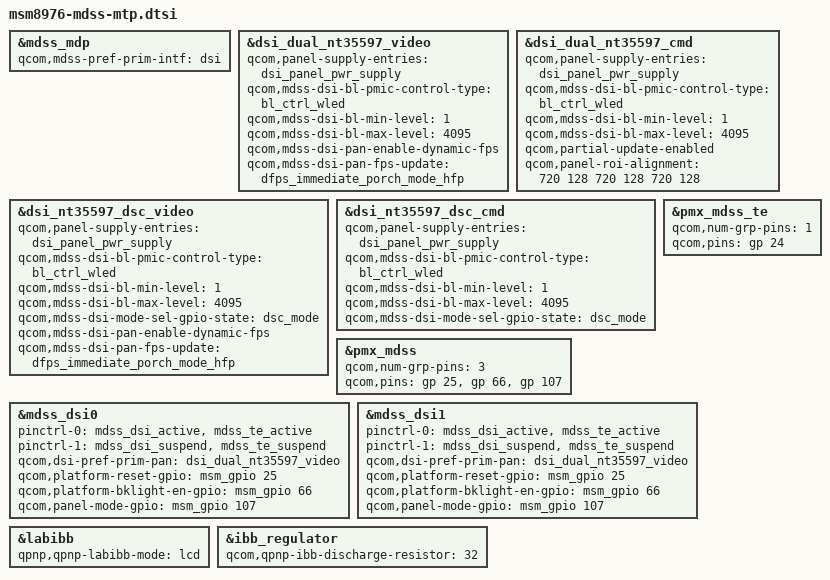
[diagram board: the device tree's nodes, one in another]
/*
 * Copyright (c) 2015, The Linux Foundation. All rights reserved.
 *
 * This program is free software; you can redistribute it and/or modify
 * it under the terms of the GNU General Public License version 2 and
 * only version 2 as published by the Free Software Foundation.
 *
 * This program is distributed in the hope that it will be useful,
 * but WITHOUT ANY WARRANTY; without even the implied warranty of
 * MERCHANTABILITY or FITNESS FOR A PARTICULAR PURPOSE.  See the
 * GNU General Public License for more details.
 */

&mdss_mdp {
	qcom,mdss-pref-prim-intf = "dsi";
};

&dsi_dual_nt35597_video {
	qcom,panel-supply-entries = <&dsi_panel_pwr_supply>;
	qcom,mdss-dsi-bl-pmic-control-type = "bl_ctrl_wled";
	qcom,mdss-dsi-bl-min-level = <1>;
	qcom,mdss-dsi-bl-max-level = <4095>;
	qcom,mdss-dsi-pan-enable-dynamic-fps;
	qcom,mdss-dsi-pan-fps-update = "dfps_immediate_porch_mode_hfp";
};

&dsi_dual_nt35597_cmd {
	qcom,panel-supply-entries = <&dsi_panel_pwr_supply>;
	qcom,mdss-dsi-bl-pmic-control-type = "bl_ctrl_wled";
	qcom,mdss-dsi-bl-min-level = <1>;
	qcom,mdss-dsi-bl-max-level = <4095>;
	qcom,partial-update-enabled;
	qcom,panel-roi-alignment = <720 128 720 128 720 128>;
};

&dsi_nt35597_dsc_video {
	qcom,panel-supply-entries = <&dsi_panel_pwr_supply>;
	qcom,mdss-dsi-bl-pmic-control-type = "bl_ctrl_wled";
	qcom,mdss-dsi-bl-min-level = <1>;
	qcom,mdss-dsi-bl-max-level = <4095>;
	qcom,mdss-dsi-mode-sel-gpio-state = "dsc_mode";
	qcom,mdss-dsi-pan-enable-dynamic-fps;
	qcom,mdss-dsi-pan-fps-update = "dfps_immediate_porch_mode_hfp";
};

&dsi_nt35597_dsc_cmd {
	qcom,panel-supply-entries = <&dsi_panel_pwr_supply>;
	qcom,mdss-dsi-bl-pmic-control-type = "bl_ctrl_wled";
	qcom,mdss-dsi-bl-min-level = <1>;
	qcom,mdss-dsi-bl-max-level = <4095>;
	qcom,mdss-dsi-mode-sel-gpio-state = "dsc_mode";
};

&pmx_mdss {
	qcom,num-grp-pins = <3>;
	qcom,pins = <&gp 25>, <&gp 66>, <&gp 107>;
};

&pmx_mdss_te {
	qcom,num-grp-pins = <1>;
	qcom,pins = <&gp 24>;
};

&mdss_dsi0 {
	pinctrl-names = "mdss_default", "mdss_sleep";
	pinctrl-0 = <&mdss_dsi_active &mdss_te_active>;
	pinctrl-1 = <&mdss_dsi_suspend &mdss_te_suspend>;
	qcom,dsi-pref-prim-pan = <&dsi_dual_nt35597_video>;

	qcom,platform-reset-gpio = <&msm_gpio 25 0>;
	qcom,platform-bklight-en-gpio = <&msm_gpio 66 0>;
	qcom,panel-mode-gpio = <&msm_gpio 107 0>;
};

&mdss_dsi1 {
	pinctrl-names = "mdss_default", "mdss_sleep";
	pinctrl-0 = <&mdss_dsi_active &mdss_te_active>;
	pinctrl-1 = <&mdss_dsi_suspend &mdss_te_suspend>;
	qcom,dsi-pref-prim-pan = <&dsi_dual_nt35597_video>;

	qcom,platform-reset-gpio = <&msm_gpio 25 0>;
	qcom,platform-bklight-en-gpio = <&msm_gpio 66 0>;
	qcom,panel-mode-gpio = <&msm_gpio 107 0>;
};

&labibb {
	status = "ok";
	qpnp,qpnp-labibb-mode = "lcd";
};

&ibb_regulator {
	qcom,qpnp-ibb-discharge-resistor = <32>;
};
